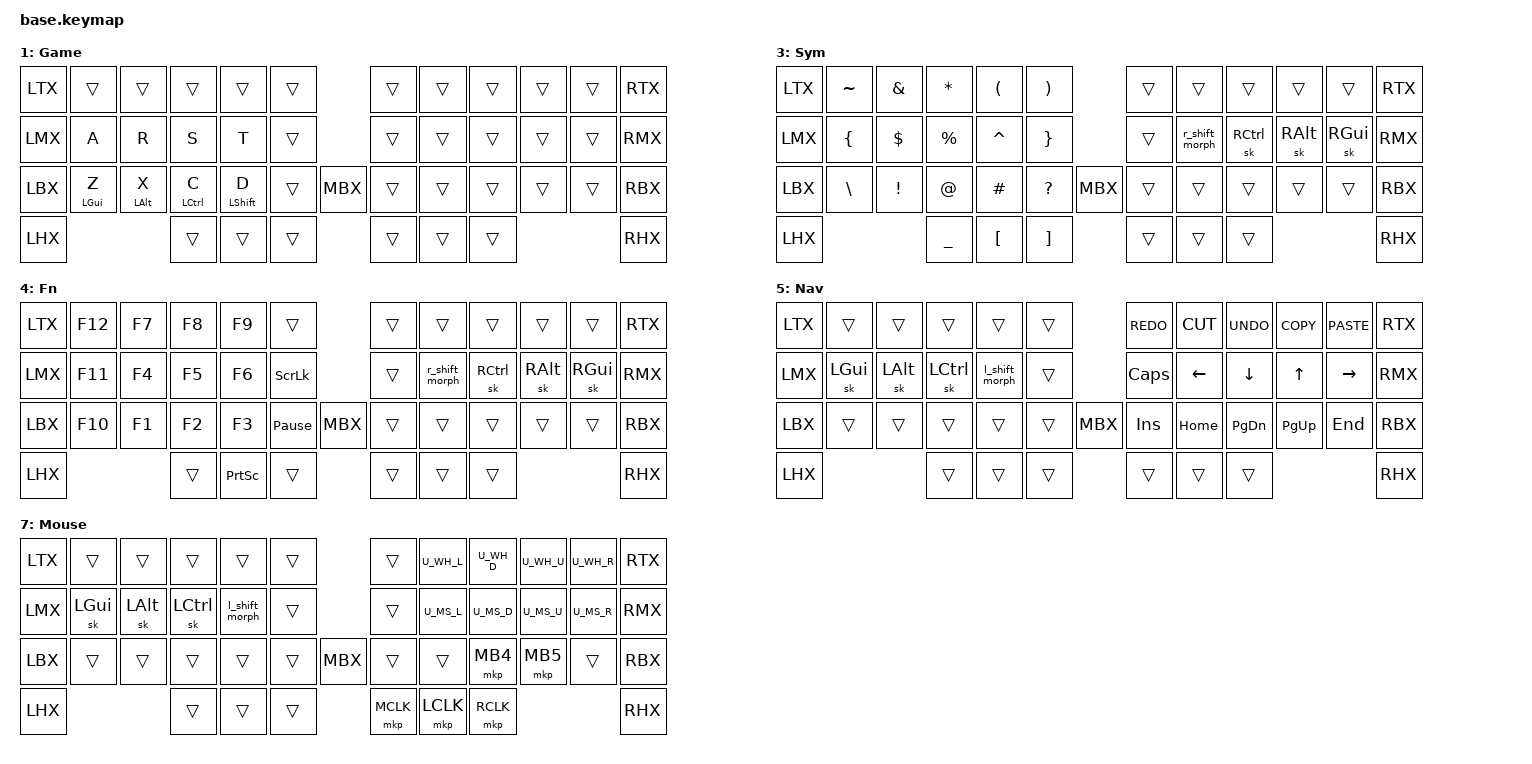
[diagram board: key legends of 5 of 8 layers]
#include <behaviors.dtsi>
#include <dt-bindings/zmk/keys.h>
#include <dt-bindings/zmk/bt.h>
#include <dt-bindings/zmk/ext_power.h>
#include <dt-bindings/zmk/outputs.h>
#define _BT_SEL_KEYS_                                                        \
    &bt BT_SEL 0 &bt BT_SEL 1 &bt BT_SEL 2 &bt BT_SEL 3
#include <dt-bindings/zmk/rgb.h>
#define _RGB_KEYS_                                                           \
  &rgb_ug RGB_BRD &rgb_ug RGB_BRI &rgb_ug RGB_EFF &rgb_ug RGB_TOG
#define BASE 0
#define GAME 1
#define NUM 2
#define SYM 3
#define FN 4
#define NAV 5
#define ADJUST 6
#define MOUSE 7

#define XXX &none
#define ___ &trans

#if defined(NICE_VIEW_SPI)
&nice_view_spi {
    cs-gpios = <NICE_VIEW_SPI>;
};
#endif
#define QUICK_TAP_MS 175
&lt {  // layer-tap config
    flavor = "balanced";
    tapping-term-ms = <200>;
    quick-tap-ms = <QUICK_TAP_MS>;
};

&sk {  // sticky-key config
    release-after-ms = <900>;  // release after 0.6s
    quick-release;             // no double capitalization when rolling keys
};

&sl {  // sticky-layer config
    ignore-modifiers;          // allow chording sticky mods & layers
};

&caps_word {
 continue-list = <UNDERSCORE MINUS BACKSPACE DELETE>;
};

// Alt+Tab swapper, requires PR #1366
// ZMK_TRI_STATE(swap,
//    bindings = <&kt LALT>, <&kp TAB>, <&kt LALT>;
//    ignored-key-positions = <LT2>;
// )

#include "keys/base.h"
#include "includes/macros.dtsi"
#include "includes/mods.dtsi"
#include "includes/combos.dtsi"
#include "includes/morphs.dtsi"
#include "includes/mouse.dtsi"


/ {
  keymap {
    compatible = "zmk,keymap";
    base_layer {
      display-name = "Base";
      bindings = <
      //╭──────╮ ╭─────────────┬─────────────┬─────────────┬─────────────┬─────────────╮          ╭─────────────┬─────────────┬─────────────┬─────────────┬─────────────╮ ╭──────╮
          _LTX    &kp Q         &kp W         &kp F         &kp P         &kp B                    &kp J         &kp L         &kp U         &kp Y         &kp SQT          _RTX
      //├──────┤ ├─────────────┼─────────────┼─────────────┼─────────────┼─────────────┤          ├─────────────┼─────────────┼─────────────┼─────────────┼─────────────┤ ├──────┤
          _LMX    &hml LGUI A   &hml LALT R   &hml LCTRL S  &hml LSHIFT T &kp G                    &kp M         &hmr RSHIFT N &hmr RCTRL E  &hmr RALT I   &hmr RGUI O      _RMX
      //├──────┤ ├─────────────┼─────────────┼─────────────┼─────────────┼─────────────┤          ├─────────────┼─────────────┼─────────────┼─────────────┼─────────────┤ ├──────┤
          _LBX    &kp Z         &kp X         &kp C         &kp D         &kp V            _MBX    &kp K         &kp H         &comma_morph  &dot_morph    &qmark_morph     _RBX
      //├──────┤ ╰─────────────┴─────────────┼─────────────┼─────────────┼─────────────┤          ├─────────────┼─────────────┼─────────────┼─────────────┴─────────────╯ ├──────┤
          _LHX                               &lt ADJUST ESC &lt NAV SPACE &lt MOUSE TAB            &lt SYM RET   &bspc_morph   &smart_shift FN 0                            _RHX
      //╰──────╯                             ╰─────────────┴─────────────┴─────────────╯          ╰─────────────┴─────────────┴─────────────╯                             ╰──────╯
      >;
      sensor-bindings = <&inc_dec_kp C_VOL_UP C_VOL_DN>;
    };
    game_layer {
      display-name = "Game";
      bindings = <
      //╭──────╮ ╭─────────────┬─────────────┬─────────────┬─────────────┬─────────────╮          ╭─────────────┬─────────────┬─────────────┬─────────────┬─────────────╮ ╭──────╮
          _LTX    ___           ___           ___           ___           ___                      ___           ___           ___           ___           ___              _RTX
      //├──────┤ ├─────────────┼─────────────┼─────────────┼─────────────┼─────────────┤          ├─────────────┼─────────────┼─────────────┼─────────────┼─────────────┤ ├──────┤
          _LMX    &kp A         &kp R         &kp S         &kp T         ___                      ___           ___           ___           ___           ___              _RMX
      //├──────┤ ├─────────────┼─────────────┼─────────────┼─────────────┼─────────────┤          ├─────────────┼─────────────┼─────────────┼─────────────┼─────────────┤ ├──────┤
          _LBX    &hml LGUI Z   &hml LALT X   &hml LCTRL C  &hml LSHIFT D ___              _MBX    ___           ___           ___           ___           ___              _RBX
      //├──────┤ ╰─────────────┴─────────────┼─────────────┼─────────────┼─────────────┤          ├─────────────┼─────────────┼─────────────┼─────────────┴─────────────╯ ├──────┤
          _LHX                                ___           ___           ___                      ___           ___           ___                                          _RHX
      //╰──────╯                             ╰─────────────┴─────────────┴─────────────╯          ╰─────────────┴─────────────┴─────────────╯                             ╰──────╯
      >;
      sensor-bindings = <&inc_dec_kp C_VOL_UP C_VOL_DN>;
    };
    num_layer {
      display-name = "Num";
      bindings = <
      //╭──────╮ ╭─────────────┬─────────────┬─────────────┬─────────────┬─────────────╮          ╭─────────────┬─────────────┬─────────────┬─────────────┬─────────────╮ ╭──────╮
          _LTX    &kp GRAVE     &kp N7        &kp N8        &kp N9        &kp AT                   &kp PRCNT     &kp LBRC      &kp LPAR      &kp RPAR      &kp RBRC         _RTX
      //├──────┤ ├─────────────┼─────────────┼─────────────┼─────────────┼─────────────┤          ├─────────────┼─────────────┼─────────────┼─────────────┼─────────────┤ ├──────┤
          _LMX    &kp DOT       &kp N4        &kp N5        &kp N6        &plus_morph              &kp HASH      &r_shift_morph &sk RCTL     &sk RALT      &sk RGUI         _RMX
      //├──────┤ ├─────────────┼─────────────┼─────────────┼─────────────┼─────────────┤          ├─────────────┼─────────────┼─────────────┼─────────────┼─────────────┤ ├──────┤
          _LBX    &kp PIPE      &kp N1        &kp N2        &kp N3        &kp AMPS         _MBX    &kp STAR      &kp UNDER     &kp LT        &kp GT        &qmark_morph     _RBX
      //├──────┤ ╰─────────────┴─────────────┼─────────────┼─────────────┼─────────────┤          ├─────────────┼─────────────┼─────────────┼─────────────┴─────────────╯ ├──────┤
          _LHX                                &kp N0        &kp MINUS     &kp EQUAL                ___           ___           ___                                          _RHX
      //╰──────╯                             ╰─────────────┴─────────────┴─────────────╯          ╰─────────────┴─────────────┴─────────────╯                             ╰──────╯
      >;
      sensor-bindings = <&inc_dec_kp C_VOL_UP C_VOL_DN>;
    };
    sym_layer {
      display-name = "Sym";
      bindings = <
      //╭──────╮ ╭─────────────┬─────────────┬─────────────┬─────────────┬─────────────╮          ╭─────────────┬─────────────┬─────────────┬─────────────┬─────────────╮ ╭──────╮
          _LTX    &kp TILDE     &kp AMPS      &kp STAR      &kp LPAR      &kp RPAR                 ___           ___           ___           ___           ___              _RTX
      //├──────┤ ├─────────────┼─────────────┼─────────────┼─────────────┼─────────────┤          ├─────────────┼─────────────┼─────────────┼─────────────┼─────────────┤ ├──────┤
          _LMX    &kp LBRC      &kp DLLR      &kp PRCNT     &kp CARET     &kp RBRC                 ___          &r_shift_morph &sk RCTRL     &sk RALT      &sk RGUI         _RMX
      //├──────┤ ├─────────────┼─────────────┼─────────────┼─────────────┼─────────────┤          ├─────────────┼─────────────┼─────────────┼─────────────┼─────────────┤ ├──────┤
          _LBX    &kp BSLH      &kp EXCL      &kp AT        &kp HASH      &kp QMARK        _MBX    ___           ___           ___           ___           ___              _RBX
      //├──────┤ ╰─────────────┴─────────────┼─────────────┼─────────────┼─────────────┤          ├─────────────┼─────────────┼─────────────┼─────────────┴─────────────╯ ├──────┤
          _LHX                                &kp UNDER     &kp LBKT      &kp RBKT                 ___           ___           ___                                          _RHX
      //╰──────╯                             ╰─────────────┴─────────────┴─────────────╯          ╰─────────────┴─────────────┴─────────────╯                             ╰──────╯
      >;
      sensor-bindings = <&inc_dec_kp C_VOL_UP C_VOL_DN>;
    };
    fn_layer {
      display-name = "Fn";
      bindings = <
      //╭──────╮ ╭─────────────┬─────────────┬─────────────┬─────────────┬─────────────╮          ╭─────────────┬─────────────┬─────────────┬─────────────┬─────────────╮ ╭──────╮
          _LTX    &kp F12       &kp F7        &kp F8        &kp F9        ___                      ___           ___           ___           ___           ___              _RTX
      //├──────┤ ├─────────────┼─────────────┼─────────────┼─────────────┼─────────────┤          ├─────────────┼─────────────┼─────────────┼─────────────┼─────────────┤ ├──────┤
          _LMX    &kp F11       &kp F4        &kp F5        &kp F6        &kp SLCK                 ___          &r_shift_morph &sk RCTRL     &sk RALT      &sk RGUI         _RMX
      //├──────┤ ├─────────────┼─────────────┼─────────────┼─────────────┼─────────────┤          ├─────────────┼─────────────┼─────────────┼─────────────┼─────────────┤ ├──────┤
          _LBX    &kp F10       &kp F1        &kp F2        &kp F3        &kp PAUSE_BREAK  _MBX    ___           ___           ___           ___           ___              _RBX
      //├──────┤ ╰─────────────┴─────────────┼─────────────┼─────────────┼─────────────┤          ├─────────────┼─────────────┼─────────────┼─────────────┴─────────────╯ ├──────┤
          _LHX                                ___           &kp PSCRN     ___                      ___           ___           ___                                          _RHX
      //╰──────╯                             ╰─────────────┴─────────────┴─────────────╯          ╰─────────────┴─────────────┴─────────────╯                             ╰──────╯
      >;
      sensor-bindings = <&inc_dec_kp C_VOL_UP C_VOL_DN>;
    };
    nav_layer {
      display-name = "Nav";
      bindings = <
      //╭──────╮ ╭─────────────┬─────────────┬─────────────┬─────────────┬─────────────╮          ╭─────────────┬─────────────┬─────────────┬─────────────┬─────────────╮ ╭──────╮
          _LTX    ___           ___           ___           ___           ___                      &kp K_REDO    &kp K_CUT     &kp K_UNDO    &kp K_COPY    &kp K_PASTE      _RTX
      //├──────┤ ├─────────────┼─────────────┼─────────────┼─────────────┼─────────────┤          ├─────────────┼─────────────┼─────────────┼─────────────┼─────────────┤ ├──────┤
          _LMX    &sk LGUI      &sk LALT      &sk LCTRL    &l_shift_morph ___                      &kp CAPS      &kp LEFT      &kp DOWN      &kp UP        &kp RIGHT        _RMX
      //├──────┤ ├─────────────┼─────────────┼─────────────┼─────────────┼─────────────┤          ├─────────────┼─────────────┼─────────────┼─────────────┼─────────────┤ ├──────┤
          _LBX    ___           ___           ___           ___           ___              _MBX    &kp INS       &kp HOME      &kp PG_DN     &kp PG_UP     &kp END          _RBX
      //├──────┤ ╰─────────────┴─────────────┼─────────────┼─────────────┼─────────────┤          ├─────────────┼─────────────┼─────────────┼─────────────┴─────────────╯ ├──────┤
          _LHX                                ___           ___           ___                      ___           ___           ___                                          _RHX
      //╰──────╯                             ╰─────────────┴─────────────┴─────────────╯          ╰─────────────┴─────────────┴─────────────╯                             ╰──────╯
      >;
      sensor-bindings = <&inc_dec_kp C_VOL_UP C_VOL_DN>;
    };
    adjust_layer {
      display-name = "Adjust";
      bindings = <
      //╭──────╮ ╭─────────────┬─────────────┬─────────────┬─────────────┬─────────────╮          ╭─────────────┬─────────────┬─────────────┬─────────────┬─────────────╮ ╭──────╮
          _LTX                                _BT_SEL_KEYS_               ___                      ___       &ext_power EP_TOG &kp C_BRI_DN  &kp C_BRI_UP  ___              _RTX
      //├──────┤ ├─────────────┼─────────────┼─────────────┼─────────────┼─────────────┤          ├─────────────┼─────────────┼─────────────┼─────────────┼─────────────┤ ├──────┤
          _LMX    ___           ___           ___           ___           &bootloader              &bootloader   &kp C_MUTE    &kp C_VOL_DN  &kp C_VOL_UP  ___              _RMX
      //├──────┤ ├─────────────┼─────────────┼─────────────┼─────────────┼─────────────┤          ├─────────────┼─────────────┼─────────────┼─────────────┼─────────────┤ ├──────┤
          _LBX                                _RGB_KEYS_                  &sys_reset       _MBX    &sys_reset    &bt BT_CLR    &bt BT_PRV    &bt BT_NXT    ___              _RBX
      //├──────┤ ╰─────────────┴─────────────┼─────────────┼─────────────┼─────────────┤          ├─────────────┼─────────────┼─────────────┼─────────────┴─────────────╯ ├──────┤
          _LHX                                ___           ___           ___                      &kp C_PP      &kp C_PREV    &kp C_NEXT                                   _RHX
      //╰──────╯                             ╰─────────────┴─────────────┴─────────────╯          ╰─────────────┴─────────────┴─────────────╯                             ╰──────╯
      >;
      sensor-bindings = <&inc_dec_kp C_VOL_UP C_VOL_DN>;
    };
    mouse_layer {
      display-name = "Mouse";
      bindings = <
      //╭──────╮ ╭─────────────┬─────────────┬─────────────┬─────────────┬─────────────╮          ╭─────────────┬─────────────┬─────────────┬─────────────┬─────────────╮ ╭──────╮
          _LTX    ___           ___           ___           ___           ___                      ___           U_WH_L        U_WH_D        U_WH_U        U_WH_R           _RTX
      //├──────┤ ├─────────────┼─────────────┼─────────────┼─────────────┼─────────────┤          ├─────────────┼─────────────┼─────────────┼─────────────┼─────────────┤ ├──────┤
          _LMX    &sk LGUI      &sk LALT      &sk LCTRL    &l_shift_morph ___                      ___           U_MS_L        U_MS_D        U_MS_U        U_MS_R           _RMX
      //├──────┤ ├─────────────┼─────────────┼─────────────┼─────────────┼─────────────┤          ├─────────────┼─────────────┼─────────────┼─────────────┼─────────────┤ ├──────┤
          _LBX    ___           ___           ___           ___           ___              _MBX    ___           ___           &mkp MB4      &mkp MB5      ___              _RBX
      //├──────┤ ╰─────────────┴─────────────┼─────────────┼─────────────┼─────────────┤          ├─────────────┼─────────────┼─────────────┼─────────────┴─────────────╯ ├──────┤
          _LHX                                ___           ___           ___                      &mkp MCLK     &mkp LCLK     &mkp RCLK                                   _RHX
      //╰──────╯                             ╰─────────────┴─────────────┴─────────────╯          ╰─────────────┴─────────────┴─────────────╯                             ╰──────╯
      >;
      sensor-bindings = <&inc_dec_kp C_VOL_UP C_VOL_DN>;
    };
  };
};
